# XMC1400 register map
Vendor: Infineon; File version: 1.0.5 (Reference Manual v1.0)
CPU: CM0 r0p0, little endian, no MPU, no FPU, 2 interrupt priority bits
Registers are 32-bit, read-write, reset 0x0 unless marked. A register's access mark holds for its fields unless they carry their own. Offsets are from the block's base; [hi:lo] are bit positions; {n}, {i} and the like mark numbered series; 'fields as' and 'values as' point back to an identical list.

## BCCU0 — BCCU Unit 0
Base 0x50030000
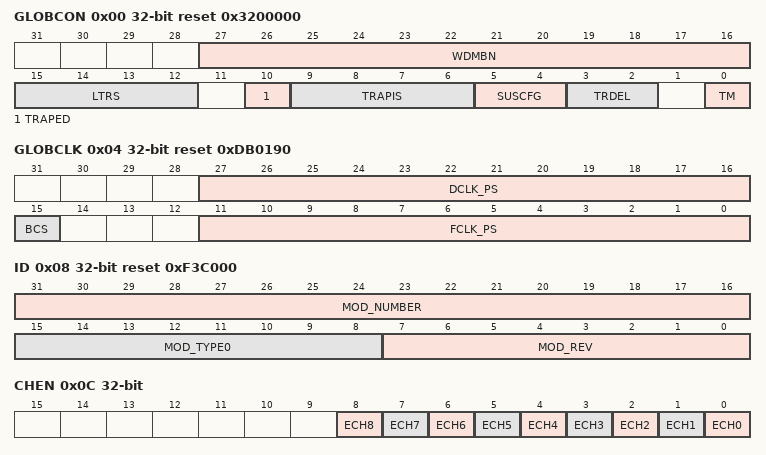
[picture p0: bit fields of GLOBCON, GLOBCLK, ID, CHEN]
0x00 GLOBCON access per field reset 0x3200000 — Global Control
  [27:16] WDMBN rw — Watchdog Maximum Bitnumber
  [15:12] LTRS ro — Last Trigger Source
    {v}=The last trigger occurred in channel turn {v} (v=0..8)
  [10] TRAPED rw — Trap Edge
    0=Trap occurs (trap flag is set) on rising edge of the BCCU.TRAPL signal; 1=Trap occurs (trap flag is set) on falling edge of the BCCU.TRAPL signal
  [9:6] TRAPIS rw — Trap Input Pin Selector
    0=BCCU.TRAPINA; 1=BCCU.TRAPINB; 2=BCCU.TRAPINC; 3=BCCU.TRAPIND; 4=BCCU.TRAPINE; 5=BCCU.TRAPINF; 6=BCCU.TRAPING; 7=BCCU.TRAPINH; 8=BCCU.TRAPINI; 9=BCCU.TRAPING; 10=BCCU.TRAPINK; 11=BCCU.TRAPINL; 12=BCCU.TRAPINM; 13=BCCU.TRAPINN; 14=BCCU.TRAPINO; 15=BCCU.TRAPINP
  [5:4] SUSCFG rw — Suspend Mode Configuration
    0=Suspend request is ignored and the module cannot get suspended; 1=All channels stop running immediately and freeze in the last state without any safe stop; 2=All channels stop running immediately and freeze in the last state; all outputs go to passive state to achieve safe stop
  [3:2] TRDEL rw — Trigger Delay
    0=No delay; 1=BCCU trigger occurs a quarter bit time after the channel trigger that caused it; only to be used if BCCU_GLOBCLK.BCS is 0; 2=BCCU trigger occurs half a bit time after the channel trigger that caused it; only to be used if BCCU_GLOBCLK.BCS is 0; 3=No delay
  [0] TM rw — Trigger Mode
    0=Mode 0: BCCU trigger occurs if there is any channel trigger (OR logic); 1=Mode 1: BCCU trigger occurs if there is a channel trigger event on the active channel. When this happens, the next trigger-enabled channel will be active following the round robin.
0x04 GLOBCLK reset 0xDB0190 — Global Clock
  [27:16] DCLK_PS — Dimmer Clock Prescaler Factor
    0=No clock; 1=Divide by 1; 0xFFF=Divide by 4095
  [15] BCS — Bit-Clock Selector
    0=Normal Mode: BCCU_bclk is generated from BCCU_fclk by a division of 4; 1=Fast Mode: BCCU_bclk is the same as BCCU_fclk
  [11:0] FCLK_PS — Fast Clock Prescaler Factor
    0=No clock; 1=Divide by 1; 0xFFF=Divide by 4095
0x08 ID ro reset 0xF3C000 (reset mask 0xFFFFFF00) — Module Identification
  [31:16] MOD_NUMBER — Module Number Value
  [15:8] MOD_TYPE0 — Module Type
  [7:0] MOD_REV — Module Revision Number
0x0C CHEN — Channel Enable
  [all] fields
    0=Channel is disabled, the output level is passive; the Linear Walker and the Sigma-Delta Modulator are reset, the Packer FIFO is flushed; all internal logic and INTy are reset when the channel gets disabled; 1=Channel is enabled
  [n] ECH{n} (n=0..8) — Channel {n} Enable
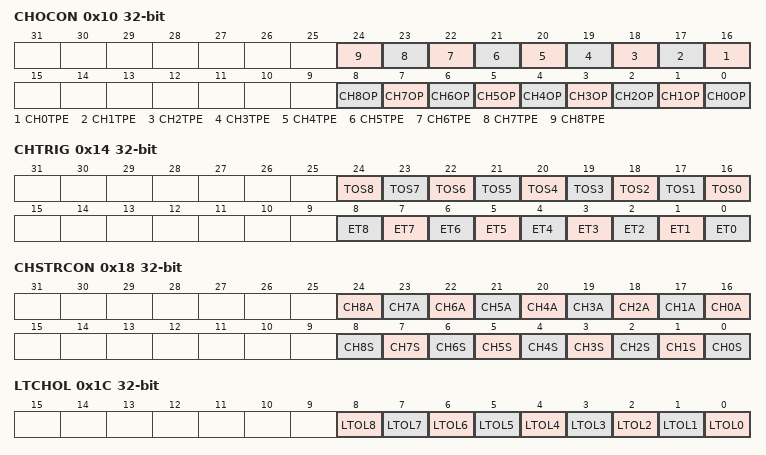
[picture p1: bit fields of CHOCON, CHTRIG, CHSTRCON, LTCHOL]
0x10 CHOCON — Channel Output Control
  [n+16] CH{n}TPE (n=0..8) — Channel {n} Trap Enable
    0=Trap function on channel is disabled; 1=Trap function on channel is enabled, the output goes to passive level when trap occurs
  [n] CH{n}OP (n=0..8) — Channel {n} Output Passive Level
    0=Active high; 1=Active low
0x14 CHTRIG — Channel Trigger
  [n+16] TOS{n} (n=0..8) — Channel {n} Trigger Output Select
    0=The channel trigger pulse will appear on BCCU_TRIGOUT0; 1=The channel trigger pulse will appear on BCCU_TRIGOUT1
  [n] ET{n} (n=0..8) — Channel {n} Trigger Enable
    0=Channel trigger is disabled; 1=Channel trigger is enabled
0x18 CHSTRCON access per field — Channel Shadow Transfer
  [n+16] CH{n}A wo (n=0..8) — Channel {n} Linear Walk Abort
    0=No action; 1=Abort linear walk; CHyS is cleared, channel y intensity stops changing
  [n] CH{n}S rw (n=0..8) — Channel {n} Shadow Transfer
    0=No action; 1=Initiate channel y target intensity shadow transfer. The linear walk will start and channel y intensity will start to change towards the target. Cleared by hardware when the linear walk is complete and the target has been reached.
0x1C LTCHOL ro — Last Trigger Channel Output Level
  [all] fields
    0=Passive; 1=Active
  [n] LTOL{n} (n=0..8) — Last Trigger Channel Output
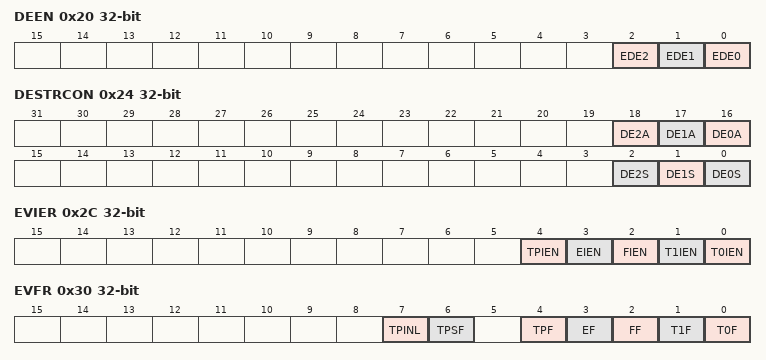
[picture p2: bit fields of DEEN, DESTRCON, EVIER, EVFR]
0x20 DEEN — Dimming Engine Enable
  [all] fields
    0=Dimming Engine is disabled;Channel brightness gets written with the value of channel intensity; 1=Dimming Engine is enabled
  [2] EDE2 — Dimming Engine 2 Enable
  [1] EDE1 — Dimming Engine 1 Enable
  [0] EDE0 — Dimming Engine 0 Enable
0x24 DESTRCON access per field — Dimming Shadow Transfer
  [18] DE2A wo — Dimming Engine 2 Dimming Abort
    0=No action; 1=Abort dimming; DEzS is cleared, BCCU_DLz.DLEV stops changing
  [17] DE1A wo — Dimming Engine 1 Dimming Abort
    values as DE2A
  [16] DE0A wo — Dimming Engine 0 Dimming Abort
    values as DE2A
  [2] DE2S rw — Dimming Engine 2 Shadow Transfer
    0=No action; 1=Initiate target dimming level shadow transfer. The dimming process will start and the dimming level will change towards the target. Cleared by hardware when the dimming process is complete and the target has been reached after the configured dimming period.
  [1] DE1S rw — Dimming Engine 1 Shadow Transfer
    values as DE2S
  [0] DE0S rw — Dimming Engine 0 Shadow Transfer
    values as DE2S
0x28 GLOBDIM — Global Dimming Level
  [11:0] GLOBDIM
0x2C EVIER — Event Interrupt Enable
  [4] TPIEN — Trap Interrupt Enable
    0=Trap interrupt generation is disabled; 1=An interrupt is generated on SR0 if a trap occurs
  [3] EIEN — FIFO Empty Interrupt Enable
    0=FIFO-full interrupt generation is disabled; 1=An interrupt is generated on SR0 if any of the packer FIFOs is empty when there is a read attempt by the output generator
  [2] FIEN — FIFO Full Interrupt Enable
    0=FIFO-full interrupt generation is disabled; 1=An interrupt is generated on SR0 if any of the packer FIFOs is full when there is a write attempt by the on-time or off-time counter
  [1] T1IEN — Trigger 1 Interrupt Enable
    0=Trigger 1 interrupt generation is disabled; 1=BCCU trigger 1 (BCCU_TRIGOUT1) generates an interrupt on SR0
  [0] T0IEN — Trigger 0 Interrupt Enable
    0=Trigger 0 interrupt generation is disabled; 1=BCCU trigger 0 (BCCU_TRIGOUT0) generates an interrupt on SR0
0x30 EVFR ro — Event Flag
  [7] TPINL — Trap Input Level
    0=The current level of BCCU.TRAPL is low; 1=The current level of BCCU.TRAPL is high
  [6] TPSF — Trap State Flag
    0=BCCU is not in a trap state; 1=BCCU is in a trap state, the affected channel outputs are at their passive levels
  [4] TPF — Trap Flag
    0=No trap event has been detected; 1=A trap event has been detected
  [3] EF — FIFO Empty Flag
    0=No FIFO full event has been detected; 1=A FIFO full event has been detected because one of the packer FIFOs is empty and there has been a read attempt by the output generator
  [2] FF — FIFO Full Flag
    0=No FIFO full event has been detected; 1=A FIFO full event has been detected because one of the packer FIFOs is full and there has been a write attempt by the on-time or off-time counter
  [1] T1F — Trigger 1 Flag
    0=No trigger event has been detected on BCCU trigger line 1 (BCCU_TRIGOUT1); 1=A trigger event has been detected on BCCU trigger line 1 (BCCU_TRIGOUT1)
  [0] T0F — Trigger 0 Flag
    0=No trigger event has been detected on BCCU trigger line 0 (BCCU_TRIGOUT0); 1=A trigger event has been detected on BCCU trigger line 0 (BCCU_TRIGOUT0)
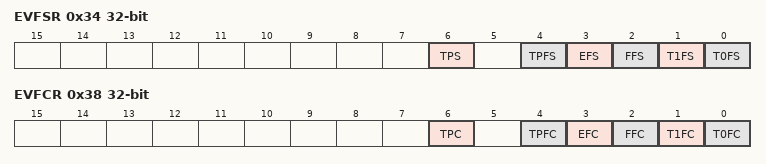
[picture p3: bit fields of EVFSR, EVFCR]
0x34 EVFSR wo — Event Flag Set
  [6] TPS — Trap Set
    0=No action; 1=Sets the Trap State Flag and Trap Flag in EVFR, a trap will be generated and an interrupt will be generated if enabled in EVIER
  [4] TPFS — Trap Flag Set
    0=No action; 1=Sets the Trap Flag in EVFR and an interrupt will be generated if enabled in EVIER, no trap will occur
  [3] EFS — FIFO Empty Flag Set
    0=No action; 1=Sets the FIFO Empty Flag in EVFR and an interrupt will be generated if enabled in EVIER
  [2] FFS — FIFO Full Flag Set
    0=No action; 1=Sets the FIFO Full Flag in EVFR and an interrupt will be generated if enabled in EVIER
  [1] T1FS — Trigger 1 Flag Set
    0=No action; 1=Sets the Trigger 1 Flag in EVFR and an interrupt will be generated if enabled in EVIER
  [0] T0FS — Trigger 0 Flag Set
    0=No action; 1=Sets the Trigger 0 Flag in EVFR and an interrupt will be generated if enabled in EVIER
0x38 EVFCR wo — Event Flag Clear
  [6] TPC — Trap Clear
    0=No action; 1=Clears the Trap State Flag in EVFR; trap state is exited, the affected channels will return to their normal output levels
  [4] TPFC — Trap Flag Clear
    0=No action; 1=Clears the Trap Flag in EVFR
  [3] EFC — FIFO Empty Flag Clear
    0=No action; 1=Clears the FIFO Empty Flag in EVFR
  [2] FFC — FIFO Full Flag Clear
    0=No action; 1=Clears the FIFO Full Flag in EVFR
  [1] T1FC — Trigger 1 Flag Clear
    0=No action; 1=Clears the Trigger 1 Flag in EVFR
  [0] T0FC — Trigger 0 Flag Clear
    0=No action; 1=Clears the Trigger 0 Flag in EVFR
